# M4KM register map
File version: 0.1
Registers are 32-bit, read-write, reset 0x0 unless marked. A register's access mark holds for its fields unless they carry their own. Offsets are from the block's base; [hi:lo] are bit positions; {n}, {i} and the like mark numbered series; 'fields as' and 'values as' point back to an identical list.

## IA — Interrupt control A Register (IA)
Base 0x4003E000
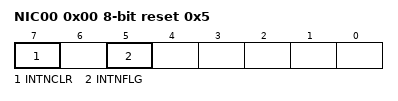
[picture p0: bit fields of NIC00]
0x00 NIC00 8-bit reset 0x5 — Non Maskable Interrupt Control Register(A) 00
  [7] INTNCLR wo, [5] INTNFLG ro

## RLM — Reset Low power Managiment Register (RLM)
Base 0x4003E400
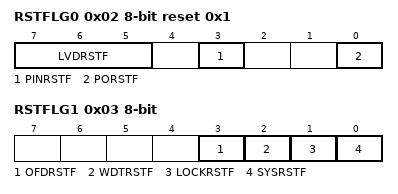
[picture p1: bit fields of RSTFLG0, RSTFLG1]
0x02 RSTFLG0 8-bit reset 0x1 (reset mask 0x1) — Reset flag register 0
  [7:5] LVDRSTF, [3] PINRSTF, [0] PORSTF
0x03 RSTFLG1 8-bit — Reset flag register 1
  [3] OFDRSTF, [2] WDTRSTF, [1] LOCKRSTF, [0] SYSRSTF

## LVD — Voltage detection circuit (LVD)
Base 0x4003EC00
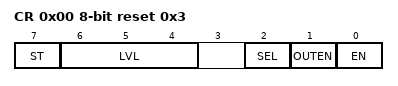
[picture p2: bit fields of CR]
0x00 CR 8-bit reset 0x3 — LVD Control register
  [7] ST ro, [6:4] LVL, [2] SEL, [1] OUTEN, [0] EN

## RPAR0 — RAM Parity (RAMP)
Base 0x40043000
Same registers: RPAR1 0x400A3000
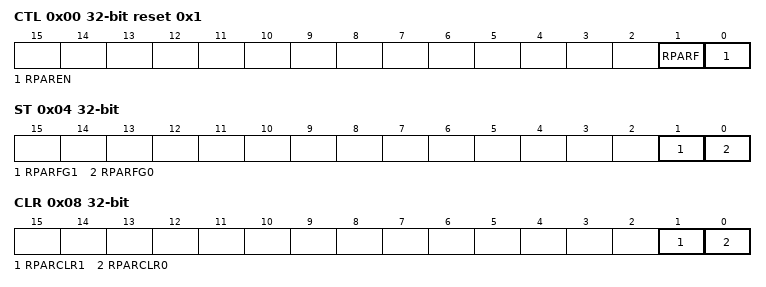
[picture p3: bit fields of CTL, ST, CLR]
0x00 CTL reset 0x1 — RAM Parity control register
  [1] RPARF, [0] RPAREN
0x04 ST ro — RAM Parity status register
  [1] RPARFG1, [0] RPARFG0
0x08 CLR wo — RAM Parity status clear register
  [1] RPARCLR1, [0] RPARCLR0
0x0C EAD0 ro — RAM Parity Error address register 0
  [31:0] RPAREADD0
0x10 EAD1 ro — RAM Parity Error address register 1
  [31:0] RPAREADD1

## CRC — CRC Calculation Circuit (CRC)
Base 0x40043100
0x00 DIN — CRC input data register
  [31:0] CRCDIN
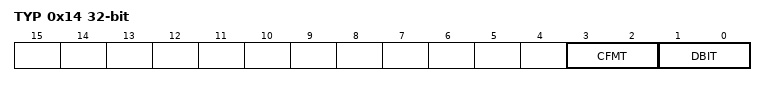
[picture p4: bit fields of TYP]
0x14 TYP — CRC data type register
  [3:2] CFMT, [1:0] DBIT
0x2C CLC reset 0xFFFFFFFF — CRC calculation result register
  [31:0] CRCCLC

## CG — Clock Control and Operation Mode (CG)
Base 0x40083000
0x00 PROTECT reset 0xC1
  [7:0] PROTECT
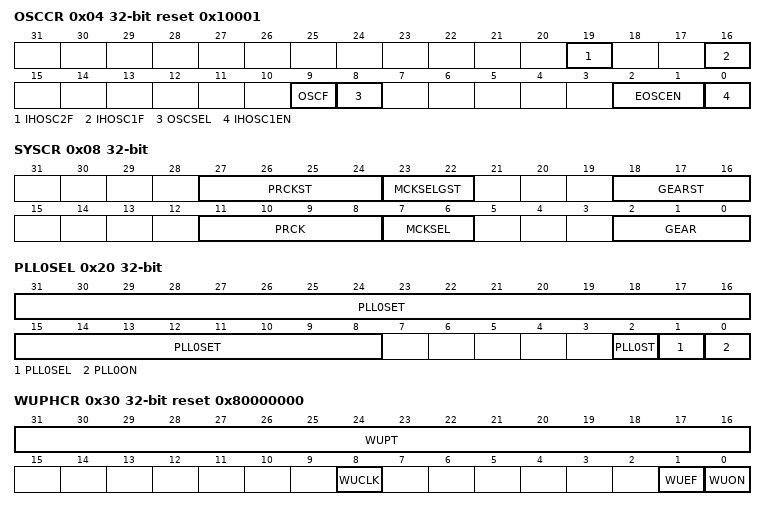
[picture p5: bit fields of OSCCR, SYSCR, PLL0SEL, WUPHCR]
0x04 OSCCR reset 0x10001 — Oscillation Control Register
  [19] IHOSC2F ro, [16] IHOSC1F ro, [9] OSCF ro, [8] OSCSEL, [2:1] EOSCEN, [0] IHOSC1EN
0x08 SYSCR — System Clock Control Register
  [27:24] PRCKST ro, [23:22] MCKSELGST ro, [18:16] GEARST ro, [11:8] PRCK, [7:6] MCKSEL, [2:0] GEAR
0x0C STBYCR — Standby Control Register
  [1:0] STBY
0x20 PLL0SEL — PLL Selection Register 0
  [31:8] PLL0SET, [2] PLL0ST ro, [1] PLL0SEL, [0] PLL0ON
0x30 WUPHCR reset 0x80000000 — High speed OSC Warming-up Register
  [31:16] WUPT, [8] WUCLK, [1] WUEF ro, [0] WUON wo
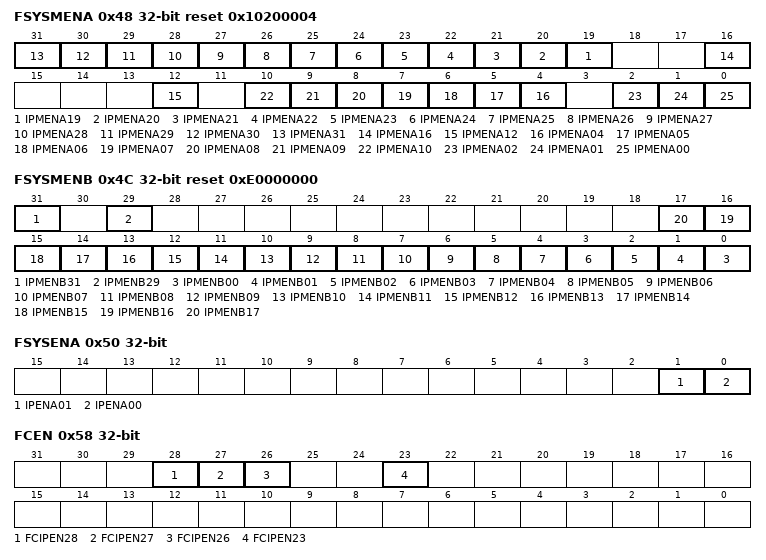
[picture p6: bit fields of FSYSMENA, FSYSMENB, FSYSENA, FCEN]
0x48 FSYSMENA reset 0x10200004 — Middle fsys Supply Stop Register A
  [n] IPMENA{n} (n=19..31), [16] IPMENA16, [12] IPMENA12, [n] IPMENA{n:02} (n=4..10), [2] IPMENA02, [1] IPMENA01, [0] IPMENA00
0x4C FSYSMENB reset 0xE0000000 — Middle fsys Supply Stop Register B
  [31] IPMENB31, [29] IPMENB29, [n] IPMENB{n:02} (n=0..17)
0x50 FSYSENA — High fsys Supply Stop Register A
  [1] IPENA01, [0] IPENA00
0x58 FCEN — FC Supply Stop Register
  [28] FCIPEN28, [27] FCIPEN27, [26] FCIPEN26, [23] FCIPEN23
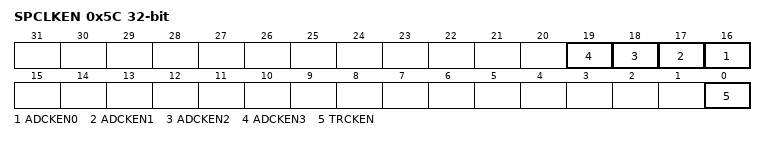
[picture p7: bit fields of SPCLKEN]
0x5C SPCLKEN — ADC_TRACE Clock Supply Stop Register
  [n+16] ADCKEN{n} (n=0..3), [0] TRCKEN

## IB — Interrupt Control B Register (IB)
Base 0x40083200
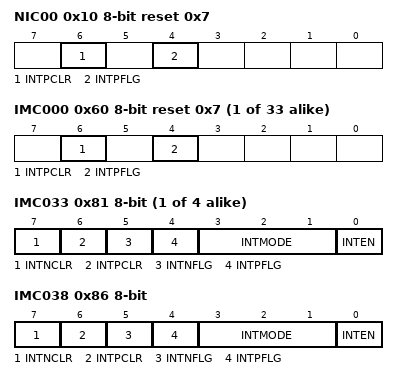
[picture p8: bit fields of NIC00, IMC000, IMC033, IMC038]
0x10 NIC00 8-bit reset 0x7 — Non maskable Interrupt Control Register(B) 00
  [6] INTPCLR wo, [4] INTPFLG ro
{0x60+i} IMC{i:03} 8-bit reset 0x7 (i=0..32) — Interrupt Mode Control Register(B) {i:03}
  [6] INTPCLR wo, [4] INTPFLG ro
{0x60+i} IMC{i:03} 8-bit (i=33..36) — Interrupt Mode Control Register(B) {i:03}
  [7] INTNCLR wo, [6] INTPCLR wo, [5] INTNFLG ro, [4] INTPFLG ro, [3:1] INTMODE, [0] INTEN
0x86 IMC038 8-bit — Interrupt Mode Control Register(B) 038
  fields as IMC033
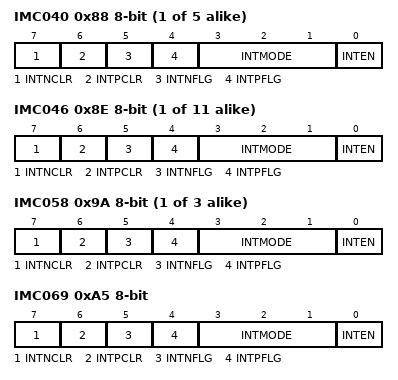
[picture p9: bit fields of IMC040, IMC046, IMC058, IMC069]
{0x60+i} IMC{i:03} 8-bit (i=40..44) — Interrupt Mode Control Register(B) {i:03}
  fields as IMC033
{0x60+i} IMC{i:03} 8-bit (i=46..56) — Interrupt Mode Control Register(B) {i:03}
  fields as IMC033
{0x60+i} IMC{i:03} 8-bit (i=58..60) — Interrupt Mode Control Register(B) {i:03}
  fields as IMC033
0xA5 IMC069 8-bit — Interrupt Mode Control Register(B) 069
  fields as IMC033

## IMN — Interrupt Monitor Register (IMN)
Base 0x40083300
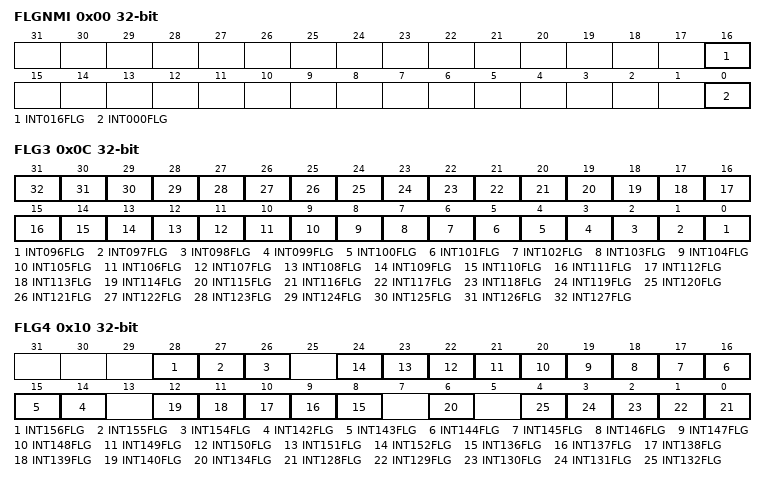
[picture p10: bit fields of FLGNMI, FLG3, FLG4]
0x00 FLGNMI ro — NMI Interrupt Monitor Flag
  [16] INT016FLG, [0] INT000FLG
0x0C FLG3 ro — Interrupt Monitor Flag 3 (096 - 127)
  [n-96] INT{n:03}FLG (n=96..127)
0x10 FLG4 ro — Interrupt Monitor Flag 4 (128 - 159)
  [28] INT156FLG, [27] INT155FLG, [26] INT154FLG, [n-128] INT{n}FLG (n=142..152), [n-128] INT{n}FLG (n=136..140), [6] INT134FLG, [n-128] INT{n}FLG (n=128..132)
0x14 FLG5 ro — Interrupt Monitor Flag 5 (160 - 191)
  [5] INT165FLG
